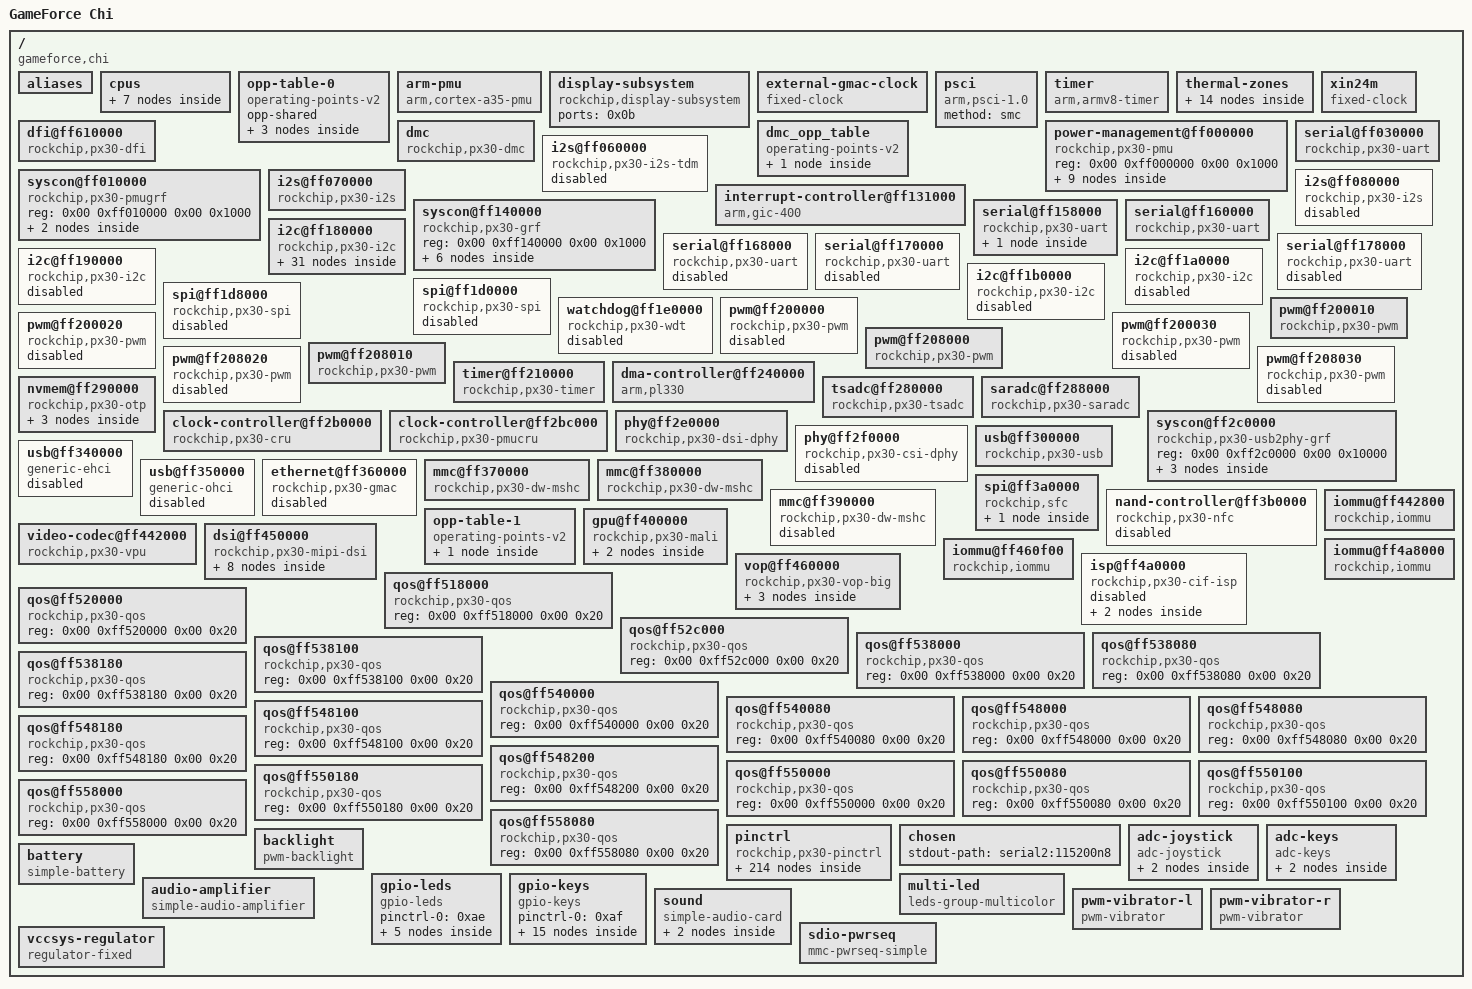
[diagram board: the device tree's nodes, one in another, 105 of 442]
/dts-v1/;

/ {
	compatible = "gameforce,chi\0rockchip,rk3326";
	interrupt-parent = <0x01>;
	#address-cells = <0x02>;
	#size-cells = <0x02>;
	model = "GameForce Chi";
	chassis-type = "handset";

	aliases {
		ethernet0 = "/ethernet@ff360000";
		i2c0 = "/i2c@ff180000";
		i2c1 = "/i2c@ff190000";
		i2c2 = "/i2c@ff1a0000";
		i2c3 = "/i2c@ff1b0000";
		serial0 = "/serial@ff030000";
		serial1 = "/serial@ff158000";
		serial2 = "/serial@ff160000";
		serial3 = "/serial@ff168000";
		serial4 = "/serial@ff170000";
		serial5 = "/serial@ff178000";
		spi0 = "/spi@ff1d0000";
		spi1 = "/spi@ff1d8000";
		mmc0 = "/mmc@ff370000";
		mmc1 = "/mmc@ff380000";
	};

	cpus {
		#address-cells = <0x02>;
		#size-cells = <0x00>;

		cpu@0 {
			device_type = "cpu";
			compatible = "arm,cortex-a35";
			reg = <0x00 0x00>;
			enable-method = "psci";
			clocks = <0x02 0x07>;
			#cooling-cells = <0x02>;
			cpu-idle-states = <0x03 0x04>;
			dynamic-power-coefficient = <0x5a>;
			operating-points-v2 = <0x05>;
			cpu-supply = <0x06>;
			phandle = <0x07>;
		};

		cpu@1 {
			device_type = "cpu";
			compatible = "arm,cortex-a35";
			reg = <0x00 0x01>;
			enable-method = "psci";
			clocks = <0x02 0x07>;
			#cooling-cells = <0x02>;
			cpu-idle-states = <0x03 0x04>;
			dynamic-power-coefficient = <0x5a>;
			operating-points-v2 = <0x05>;
			cpu-supply = <0x06>;
			phandle = <0x08>;
		};

		cpu@2 {
			device_type = "cpu";
			compatible = "arm,cortex-a35";
			reg = <0x00 0x02>;
			enable-method = "psci";
			clocks = <0x02 0x07>;
			#cooling-cells = <0x02>;
			cpu-idle-states = <0x03 0x04>;
			dynamic-power-coefficient = <0x5a>;
			operating-points-v2 = <0x05>;
			cpu-supply = <0x06>;
			phandle = <0x09>;
		};

		cpu@3 {
			device_type = "cpu";
			compatible = "arm,cortex-a35";
			reg = <0x00 0x03>;
			enable-method = "psci";
			clocks = <0x02 0x07>;
			#cooling-cells = <0x02>;
			cpu-idle-states = <0x03 0x04>;
			dynamic-power-coefficient = <0x5a>;
			operating-points-v2 = <0x05>;
			cpu-supply = <0x06>;
			phandle = <0x0a>;
		};

		idle-states {
			entry-method = "psci";

			cpu-sleep {
				compatible = "arm,idle-state";
				local-timer-stop;
				arm,psci-suspend-param = <0x10000>;
				entry-latency-us = <0x78>;
				exit-latency-us = <0xfa>;
				min-residency-us = <0x384>;
				phandle = <0x03>;
			};

			cluster-sleep {
				compatible = "arm,idle-state";
				local-timer-stop;
				arm,psci-suspend-param = <0x1010000>;
				entry-latency-us = <0x190>;
				exit-latency-us = <0x1f4>;
				min-residency-us = <0x7d0>;
				phandle = <0x04>;
			};
		};
	};

	opp-table-0 {
		compatible = "operating-points-v2";
		opp-shared;
		phandle = <0x05>;

		opp-1008000000 {
			opp-hz = <0x00 0x3c14dc00>;
			opp-microvolt = <0x11edd8 0x11edd8 0x149970>;
			clock-latency-ns = <0x9c40>;
		};

		opp-1296000000 {
			opp-hz = <0x00 0x4d3f6400>;
			opp-microvolt = <0x149970 0x149970 0x149970>;
			clock-latency-ns = <0x9c40>;
		};

		opp-1416000000 {
			opp-hz = <0x00 0x54667200>;
			opp-microvolt = <0x149970 0x149970 0x149970>;
			clock-latency-ns = <0x9c40>;
			turbo-mode;
		};
	};

	arm-pmu {
		compatible = "arm,cortex-a35-pmu";
		interrupts = <0x00 0x64 0x04 0x00 0x65 0x04 0x00 0x66 0x04 0x00 0x67 0x04>;
		interrupt-affinity = <0x07 0x08 0x09 0x0a>;
	};

	display-subsystem {
		compatible = "rockchip,display-subsystem";
		ports = <0x0b>;
		status = "okay";
	};

	external-gmac-clock {
		compatible = "fixed-clock";
		clock-frequency = <0x2faf080>;
		clock-output-names = "gmac_clkin";
		#clock-cells = <0x00>;
	};

	psci {
		compatible = "arm,psci-1.0";
		method = "smc";
	};

	timer {
		compatible = "arm,armv8-timer";
		interrupts = <0x01 0x0d 0xf04 0x01 0x0e 0xf04 0x01 0x0b 0xf04 0x01 0x0a 0xf04>;
	};

	thermal-zones {

		soc-thermal {
			polling-delay-passive = <0x14>;
			polling-delay = <0x3e8>;
			sustainable-power = <0x2ee>;
			thermal-sensors = <0x0c 0x00>;

			trips {

				trip-point-0 {
					temperature = <0x11170>;
					hysteresis = <0x7d0>;
					type = "passive";
				};

				trip-point-1 {
					temperature = <0x14c08>;
					hysteresis = <0x7d0>;
					type = "passive";
					phandle = <0x0d>;
				};

				soc-crit {
					temperature = <0x1c138>;
					hysteresis = <0x7d0>;
					type = "critical";
				};
			};

			cooling-maps {

				map0 {
					trip = <0x0d>;
					cooling-device = <0x07 0xffffffff 0xffffffff>;
					contribution = <0x1000>;
				};
			};
		};

		gpu-thermal {
			polling-delay-passive = <0x64>;
			polling-delay = <0x3e8>;
			thermal-sensors = <0x0c 0x01>;

			trips {

				gpu-threshold {
					temperature = <0x11170>;
					hysteresis = <0x7d0>;
					type = "passive";
				};

				gpu-target {
					temperature = <0x14c08>;
					hysteresis = <0x7d0>;
					type = "passive";
					phandle = <0x0e>;
				};

				gpu-crit {
					temperature = <0x1c138>;
					hysteresis = <0x7d0>;
					type = "critical";
				};
			};

			cooling-maps {

				map0 {
					trip = <0x0e>;
					cooling-device = <0x0f 0xffffffff 0xffffffff>;
				};
			};
		};
	};

	xin24m {
		compatible = "fixed-clock";
		#clock-cells = <0x00>;
		clock-frequency = <0x16e3600>;
		clock-output-names = "xin24m";
		phandle = <0x74>;
	};

	power-management@ff000000 {
		compatible = "rockchip,px30-pmu\0syscon\0simple-mfd";
		reg = <0x00 0xff000000 0x00 0x1000>;

		power-controller {
			compatible = "rockchip,px30-power-controller";
			#power-domain-cells = <0x01>;
			#address-cells = <0x01>;
			#size-cells = <0x00>;
			phandle = <0x76>;

			power-domain@5 {
				reg = <0x05>;
				clocks = <0x02 0x103 0x02 0x102 0x02 0x3c>;
				pm_qos = <0x10 0x11>;
				#power-domain-cells = <0x00>;
			};

			power-domain@7 {
				reg = <0x07>;
				clocks = <0x02 0xf7 0x02 0x3b>;
				pm_qos = <0x12>;
				#power-domain-cells = <0x00>;
			};

			power-domain@9 {
				reg = <0x09>;
				clocks = <0x02 0xb2 0x02 0x143 0x02 0x40 0x02 0x3f>;
				pm_qos = <0x13>;
				#power-domain-cells = <0x00>;
			};

			power-domain@10 {
				reg = <0x0a>;
				clocks = <0x02 0xfe 0x02 0x100 0x02 0xff 0x02 0x101 0x02 0x39 0x02 0x37 0x02 0x38 0x02 0x3a>;
				pm_qos = <0x14 0x15 0x16 0x17>;
				#power-domain-cells = <0x00>;
			};

			power-domain@11 {
				reg = <0x0b>;
				clocks = <0x02 0xaf 0x02 0xf4 0x02 0x4b>;
				pm_qos = <0x18 0x19>;
				#power-domain-cells = <0x00>;
			};

			power-domain@12 {
				reg = <0x0c>;
				clocks = <0x02 0xb7 0x02 0xb5 0x02 0xb6 0x02 0x96 0x02 0x97 0x02 0xfd 0x02 0xfb 0x02 0xfc 0x02 0x144 0x02 0x35 0x02 0x36>;
				pm_qos = <0x1a 0x1b 0x1c 0x1d>;
				#power-domain-cells = <0x00>;
			};

			power-domain@13 {
				reg = <0x0d>;
				clocks = <0x02 0xb3 0x02 0xb4 0x02 0xf9 0x02 0xfa 0x02 0x33>;
				pm_qos = <0x1e 0x1f 0x20 0x21 0x22>;
				#power-domain-cells = <0x00>;
			};

			power-domain@14 {
				reg = <0x0e>;
				clocks = <0x02 0x49>;
				pm_qos = <0x23>;
				#power-domain-cells = <0x00>;
			};
		};
	};

	dfi@ff610000 {
		reg = <0x00 0xff610000 0x00 0x400>;
		compatible = "rockchip,px30-dfi";
		rockchip,pmu = <0x24>;
		status = "okay";
		phandle = <0x25>;
	};

	dmc {
		compatible = "rockchip,px30-dmc";
		devfreq-events = <0x25>;
		clocks = <0x02 0x54>;
		clock-names = "dmc_clk";
		operating-points-v2 = <0x26>;
		uptreshold = <0x28>;
		downdifferential = <0x14>;
		status = "okay";
	};

	dmc_opp_table {
		compatible = "operating-points-v2";
		phandle = <0x26>;

		opp-924000000 {
			opp-hz = <0x00 0x37131f00>;
			opp-microvolt = <0x112a88>;
		};
	};

	syscon@ff010000 {
		compatible = "rockchip,px30-pmugrf\0syscon\0simple-mfd";
		reg = <0x00 0xff010000 0x00 0x1000>;
		#address-cells = <0x01>;
		#size-cells = <0x01>;
		phandle = <0x24>;

		io-domains {
			compatible = "rockchip,px30-pmu-io-voltage-domain";
			status = "okay";
			pmuio1-supply = <0x27>;
			pmuio2-supply = <0x28>;
		};

		reboot-mode {
			compatible = "syscon-reboot-mode";
			offset = <0x200>;
			mode-bootloader = <0x5242c301>;
			mode-fastboot = <0x5242c309>;
			mode-loader = <0x5242c301>;
			mode-normal = <0x5242c300>;
			mode-recovery = <0x5242c303>;
		};
	};

	serial@ff030000 {
		compatible = "rockchip,px30-uart\0snps,dw-apb-uart";
		reg = <0x00 0xff030000 0x00 0x100>;
		interrupts = <0x00 0x0f 0x04>;
		clocks = <0x29 0x06 0x29 0x15>;
		clock-names = "baudclk\0apb_pclk";
		dmas = <0x2a 0x00 0x2a 0x01>;
		dma-names = "tx\0rx";
		reg-shift = <0x02>;
		reg-io-width = <0x04>;
		pinctrl-names = "default";
		pinctrl-0 = <0x2b 0x2c 0x2d>;
		status = "okay";
	};

	i2s@ff060000 {
		compatible = "rockchip,px30-i2s-tdm";
		reg = <0x00 0xff060000 0x00 0x1000>;
		interrupts = <0x00 0x0c 0x04>;
		clocks = <0x02 0x10 0x02 0x12 0x02 0x106>;
		clock-names = "mclk_tx\0mclk_rx\0hclk";
		dmas = <0x2a 0x10 0x2a 0x11>;
		dma-names = "tx\0rx";
		rockchip,grf = <0x2e>;
		resets = <0x02 0x84 0x02 0xbf>;
		reset-names = "tx-m\0rx-m";
		pinctrl-names = "default";
		pinctrl-0 = <0x2f 0x30 0x31 0x32 0x33 0x34 0x35 0x36 0x37 0x38 0x39 0x3a>;
		#sound-dai-cells = <0x00>;
		status = "disabled";
	};

	i2s@ff070000 {
		compatible = "rockchip,px30-i2s\0rockchip,rk3066-i2s";
		reg = <0x00 0xff070000 0x00 0x1000>;
		interrupts = <0x00 0x0d 0x04>;
		clocks = <0x02 0x14 0x02 0x107>;
		clock-names = "i2s_clk\0i2s_hclk";
		dmas = <0x2a 0x12 0x2a 0x13>;
		dma-names = "tx\0rx";
		pinctrl-names = "default";
		pinctrl-0 = <0x3b 0x3c 0x3d 0x3e>;
		#sound-dai-cells = <0x00>;
		status = "okay";
		phandle = <0xb9>;
	};

	i2s@ff080000 {
		compatible = "rockchip,px30-i2s\0rockchip,rk3066-i2s";
		reg = <0x00 0xff080000 0x00 0x1000>;
		interrupts = <0x00 0x0e 0x04>;
		clocks = <0x02 0x16 0x02 0x108>;
		clock-names = "i2s_clk\0i2s_hclk";
		dmas = <0x2a 0x14 0x2a 0x15>;
		dma-names = "tx\0rx";
		pinctrl-names = "default";
		pinctrl-0 = <0x3f 0x40 0x41 0x42>;
		#sound-dai-cells = <0x00>;
		status = "disabled";
	};

	interrupt-controller@ff131000 {
		compatible = "arm,gic-400";
		#interrupt-cells = <0x03>;
		#address-cells = <0x00>;
		interrupt-controller;
		reg = <0x00 0xff131000 0x00 0x1000 0x00 0xff132000 0x00 0x2000 0x00 0xff134000 0x00 0x2000 0x00 0xff136000 0x00 0x2000>;
		interrupts = <0x01 0x09 0xf04>;
		phandle = <0x01>;
	};

	syscon@ff140000 {
		compatible = "rockchip,px30-grf\0syscon\0simple-mfd";
		reg = <0x00 0xff140000 0x00 0x1000>;
		#address-cells = <0x01>;
		#size-cells = <0x01>;
		phandle = <0x2e>;

		io-domains {
			compatible = "rockchip,px30-io-voltage-domain";
			status = "okay";
			vccio1-supply = <0x28>;
			vccio2-supply = <0x43>;
			vccio3-supply = <0x44>;
			vccio4-supply = <0x44>;
			vccio5-supply = <0x44>;
			vccio6-supply = <0x44>;
		};

		lvds {
			compatible = "rockchip,px30-lvds";
			phys = <0x45>;
			phy-names = "dphy";
			rockchip,grf = <0x2e>;
			rockchip,output = "lvds";
			status = "disabled";

			ports {
				#address-cells = <0x01>;
				#size-cells = <0x00>;

				port@0 {
					reg = <0x00>;
					#address-cells = <0x01>;
					#size-cells = <0x00>;

					endpoint@0 {
						reg = <0x00>;
						remote-endpoint = <0x46>;
						phandle = <0x9d>;
					};
				};

				port@1 {
					reg = <0x01>;
				};
			};
		};
	};

	serial@ff158000 {
		compatible = "rockchip,px30-uart\0snps,dw-apb-uart";
		reg = <0x00 0xff158000 0x00 0x100>;
		interrupts = <0x00 0x10 0x04>;
		clocks = <0x02 0x18 0x02 0x149>;
		clock-names = "baudclk\0apb_pclk";
		reg-shift = <0x02>;
		reg-io-width = <0x04>;
		pinctrl-names = "default";
		pinctrl-0 = <0x47 0x48 0x49>;
		status = "okay";
		uart-has-rtscts;

		bluetooth {
			compatible = "realtek,rtl8723ds-bt";
			device-wake-gpios = <0x4a 0x01 0x00>;
			enable-gpios = <0x4a 0x00 0x00>;
			host-wake-gpios = <0x4a 0x07 0x00>;
			pinctrl-0 = <0x4b 0x4c 0x4d>;
			pinctrl-names = "default";
		};
	};

	serial@ff160000 {
		compatible = "rockchip,px30-uart\0snps,dw-apb-uart";
		reg = <0x00 0xff160000 0x00 0x100>;
		interrupts = <0x00 0x11 0x04>;
		clocks = <0x02 0x19 0x02 0x14a>;
		clock-names = "baudclk\0apb_pclk";
		dmas = <0x2a 0x04 0x2a 0x05>;
		dma-names = "tx\0rx";
		reg-shift = <0x02>;
		reg-io-width = <0x04>;
		pinctrl-names = "default";
		pinctrl-0 = <0x4e>;
		status = "okay";
	};

	serial@ff168000 {
		compatible = "rockchip,px30-uart\0snps,dw-apb-uart";
		reg = <0x00 0xff168000 0x00 0x100>;
		interrupts = <0x00 0x12 0x04>;
		clocks = <0x02 0x1a 0x02 0x14b>;
		clock-names = "baudclk\0apb_pclk";
		dmas = <0x2a 0x06 0x2a 0x07>;
		dma-names = "tx\0rx";
		reg-shift = <0x02>;
		reg-io-width = <0x04>;
		pinctrl-names = "default";
		pinctrl-0 = <0x4f 0x50 0x51>;
		status = "disabled";
	};

	serial@ff170000 {
		compatible = "rockchip,px30-uart\0snps,dw-apb-uart";
		reg = <0x00 0xff170000 0x00 0x100>;
		interrupts = <0x00 0x13 0x04>;
		clocks = <0x02 0x1b 0x02 0x14c>;
		clock-names = "baudclk\0apb_pclk";
		dmas = <0x2a 0x08 0x2a 0x09>;
		dma-names = "tx\0rx";
		reg-shift = <0x02>;
		reg-io-width = <0x04>;
		pinctrl-names = "default";
		pinctrl-0 = <0x52 0x53 0x54>;
		status = "disabled";
	};

	serial@ff178000 {
		compatible = "rockchip,px30-uart\0snps,dw-apb-uart";
		reg = <0x00 0xff178000 0x00 0x100>;
		interrupts = <0x00 0x14 0x04>;
		clocks = <0x02 0x1c 0x02 0x14d>;
		clock-names = "baudclk\0apb_pclk";
		dmas = <0x2a 0x0a 0x2a 0x0b>;
		dma-names = "tx\0rx";
		reg-shift = <0x02>;
		reg-io-width = <0x04>;
		pinctrl-names = "default";
		pinctrl-0 = <0x55 0x56 0x57>;
		status = "disabled";
	};

	i2c@ff180000 {
		compatible = "rockchip,px30-i2c\0rockchip,rk3399-i2c";
		reg = <0x00 0xff180000 0x00 0x1000>;
		clocks = <0x02 0x1d 0x02 0x14e>;
		clock-names = "i2c\0pclk";
		interrupts = <0x00 0x07 0x04>;
		pinctrl-names = "default";
		pinctrl-0 = <0x58>;
		#address-cells = <0x01>;
		#size-cells = <0x00>;
		status = "okay";
		clock-frequency = <0x61a80>;
		i2c-scl-falling-time-ns = <0x10>;
		i2c-scl-rising-time-ns = <0x118>;

		pmic@20 {
			compatible = "rockchip,rk817";
			reg = <0x20>;
			#clock-cells = <0x01>;
			clock-names = "mclk";
			clock-output-names = "rk808-clkout1\0xin32k";
			clocks = <0x02 0x15>;
			interrupt-parent = <0x4a>;
			interrupts = <0x11 0x08>;
			pinctrl-0 = <0x59 0x5a>;
			pinctrl-names = "default";
			#sound-dai-cells = <0x00>;
			system-power-controller;
			wakeup-source;
			vcc1-supply = <0x5b>;
			vcc2-supply = <0x5b>;
			vcc3-supply = <0x5b>;
			vcc4-supply = <0x5b>;
			vcc5-supply = <0x5b>;
			vcc6-supply = <0x5b>;
			vcc7-supply = <0x44>;
			vcc8-supply = <0x5b>;
			vcc9-supply = <0x5c>;
			phandle = <0xb8>;

			regulators {

				DCDC_REG1 {
					regulator-always-on;
					regulator-boot-on;
					regulator-max-microvolt = <0x118c30>;
					regulator-min-microvolt = <0xe7ef0>;
					regulator-name = "vdd_logic";
					regulator-ramp-delay = <0x1771>;
					phandle = <0x93>;

					regulator-state-mem {
						regulator-on-in-suspend;
						regulator-suspend-microvolt = <0xe7ef0>;
					};
				};

				DCDC_REG2 {
					regulator-always-on;
					regulator-boot-on;
					regulator-max-microvolt = <0x149970>;
					regulator-min-microvolt = <0xe7ef0>;
					regulator-name = "vdd_arm";
					regulator-ramp-delay = <0x1771>;
					phandle = <0x06>;

					regulator-state-mem {
						regulator-off-in-suspend;
						regulator-suspend-microvolt = <0xe7ef0>;
					};
				};

				DCDC_REG3 {
					regulator-always-on;
					regulator-boot-on;
					regulator-name = "vcc_ddr";

					regulator-state-mem {
						regulator-on-in-suspend;
					};
				};

				DCDC_REG4 {
					regulator-always-on;
					regulator-boot-on;
					regulator-max-microvolt = <0x2dc6c0>;
					regulator-min-microvolt = <0x2dc6c0>;
					regulator-name = "vcc_3v0";
					phandle = <0x44>;

					regulator-state-mem {
						regulator-off-in-suspend;
						regulator-suspend-microvolt = <0x2dc6c0>;
					};
				};

				LDO_REG2 {
					regulator-always-on;
					regulator-boot-on;
					regulator-max-microvolt = <0x1b7740>;
					regulator-min-microvolt = <0x1b7740>;
					regulator-name = "vcc_1v8";
					phandle = <0x27>;

					regulator-state-mem {
						regulator-on-in-suspend;
						regulator-suspend-microvolt = <0x1b7740>;
					};
				};

				LDO_REG3 {
					regulator-always-on;
					regulator-boot-on;
					regulator-max-microvolt = <0xf4240>;
					regulator-min-microvolt = <0xf4240>;
					regulator-name = "vdd_1v0";

					regulator-state-mem {
						regulator-on-in-suspend;
						regulator-suspend-microvolt = <0xf4240>;
					};
				};

				LDO_REG4 {
					regulator-always-on;
					regulator-boot-on;
					regulator-max-microvolt = <0x2dc6c0>;
					regulator-min-microvolt = <0x2dc6c0>;
					regulator-name = "vcc_3v0_pmu";
					phandle = <0x28>;

					regulator-state-mem {
						regulator-on-in-suspend;
						regulator-suspend-microvolt = <0x2dc6c0>;
					};
				};

				LDO_REG5 {
					regulator-always-on;
					regulator-boot-on;
					regulator-max-microvolt = <0x325aa0>;
					regulator-min-microvolt = <0x1b7740>;
					regulator-name = "vccio_sd";
					phandle = <0x43>;

					regulator-state-mem {
						regulator-on-in-suspend;
						regulator-suspend-microvolt = <0x325aa0>;
					};
				};

				LDO_REG6 {
					regulator-boot-on;
					regulator-max-microvolt = <0x325aa0>;
					regulator-min-microvolt = <0x325aa0>;
					regulator-name = "vcc_sd";
					phandle = <0x7f>;

					regulator-state-mem {
						regulator-on-in-suspend;
						regulator-suspend-microvolt = <0x325aa0>;
					};
				};

				LDO_REG7 {
					regulator-max-microvolt = <0x325aa0>;
					regulator-min-microvolt = <0x325aa0>;
					regulator-name = "vcc_bl";
					phandle = <0xac>;

					regulator-state-mem {
						regulator-off-in-suspend;
						regulator-suspend-microvolt = <0x325aa0>;
					};
				};

				LDO_REG8 {
					regulator-max-microvolt = <0x2ab980>;
					regulator-min-microvolt = <0x2ab980>;
					regulator-name = "vcc_lcd";
					phandle = <0x98>;

					regulator-state-mem {
						regulator-off-in-suspend;
						regulator-suspend-microvolt = <0x2ab980>;
					};
				};

				LDO_REG9 {
					regulator-always-on;
					regulator-boot-on;
					regulator-max-microvolt = <0x325aa0>;
					regulator-min-microvolt = <0x325aa0>;
					regulator-name = "vcc_wifi";

					regulator-state-mem {
						regulator-off-in-suspend;
						regulator-suspend-microvolt = <0x325aa0>;
					};
				};

				BOOST {
					regulator-max-microvolt = <0x4c4b40>;
					regulator-min-microvolt = <0x4c4b40>;
					regulator-name = "dcdc_boost";
					phandle = <0x5c>;

					regulator-state-mem {
						regulator-off-in-suspend;
					};
				};

				OTG_SWITCH {
					regulator-name = "otg_switch";

					regulator-state-mem {
						regulator-off-in-suspend;
					};
				};
			};

			charger {
				monitored-battery = <0x5d>;
				rockchip,resistor-sense-micro-ohms = <0x2710>;
				rockchip,sleep-enter-current-microamp = <0x493e0>;
				rockchip,sleep-filter-current-microamp = <0x186a0>;
			};
		};
	};

	i2c@ff190000 {
		compatible = "rockchip,px30-i2c\0rockchip,rk3399-i2c";
		reg = <0x00 0xff190000 0x00 0x1000>;
		clocks = <0x02 0x1e 0x02 0x14f>;
		clock-names = "i2c\0pclk";
		interrupts = <0x00 0x08 0x04>;
		pinctrl-names = "default";
		pinctrl-0 = <0x5e>;
		#address-cells = <0x01>;
		#size-cells = <0x00>;
		status = "disabled";
	};

	i2c@ff1a0000 {
		compatible = "rockchip,px30-i2c\0rockchip,rk3399-i2c";
		reg = <0x00 0xff1a0000 0x00 0x1000>;
		clocks = <0x02 0x1f 0x02 0x150>;
		clock-names = "i2c\0pclk";
		interrupts = <0x00 0x09 0x04>;
		pinctrl-names = "default";
		pinctrl-0 = <0x5f>;
		#address-cells = <0x01>;
		#size-cells = <0x00>;
		status = "disabled";
	};

	i2c@ff1b0000 {
		compatible = "rockchip,px30-i2c\0rockchip,rk3399-i2c";
		reg = <0x00 0xff1b0000 0x00 0x1000>;
		clocks = <0x02 0x20 0x02 0x151>;
		clock-names = "i2c\0pclk";
		interrupts = <0x00 0x0a 0x04>;
		pinctrl-names = "default";
		pinctrl-0 = <0x60>;
		#address-cells = <0x01>;
		#size-cells = <0x00>;
		status = "disabled";
	};

	spi@ff1d0000 {
		compatible = "rockchip,px30-spi\0rockchip,rk3066-spi";
		reg = <0x00 0xff1d0000 0x00 0x1000>;
		interrupts = <0x00 0x1a 0x04>;
		clocks = <0x02 0x24 0x02 0x155>;
		clock-names = "spiclk\0apb_pclk";
		dmas = <0x2a 0x0c 0x2a 0x0d>;
		dma-names = "tx\0rx";
		num-cs = <0x02>;
		pinctrl-names = "default";
		pinctrl-0 = <0x61 0x62 0x63 0x64>;
		#address-cells = <0x01>;
		#size-cells = <0x00>;
		status = "disabled";
	};

	spi@ff1d8000 {
		compatible = "rockchip,px30-spi\0rockchip,rk3066-spi";
		reg = <0x00 0xff1d8000 0x00 0x1000>;
		interrupts = <0x00 0x1b 0x04>;
		clocks = <0x02 0x25 0x02 0x156>;
		clock-names = "spiclk\0apb_pclk";
		dmas = <0x2a 0x0e 0x2a 0x0f>;
		dma-names = "tx\0rx";
		num-cs = <0x02>;
		pinctrl-names = "default";
		pinctrl-0 = <0x65 0x66 0x67 0x68 0x69>;
		#address-cells = <0x01>;
		#size-cells = <0x00>;
		status = "disabled";
	};

	watchdog@ff1e0000 {
		compatible = "rockchip,px30-wdt\0snps,dw-wdt";
		reg = <0x00 0xff1e0000 0x00 0x100>;
		clocks = <0x02 0x15b>;
		interrupts = <0x00 0x25 0x04>;
		status = "disabled";
	};

	pwm@ff200000 {
		compatible = "rockchip,px30-pwm\0rockchip,rk3328-pwm";
		reg = <0x00 0xff200000 0x00 0x10>;
		clocks = <0x02 0x22 0x02 0x153>;
		clock-names = "pwm\0pclk";
		pinctrl-names = "default";
		pinctrl-0 = <0x6a>;
		#pwm-cells = <0x03>;
		status = "disabled";
	};

	pwm@ff200010 {
		compatible = "rockchip,px30-pwm\0rockchip,rk3328-pwm";
		reg = <0x00 0xff200010 0x00 0x10>;
		clocks = <0x02 0x22 0x02 0x153>;
		clock-names = "pwm\0pclk";
		pinctrl-names = "default";
		pinctrl-0 = <0x6b>;
		#pwm-cells = <0x03>;
		status = "okay";
		phandle = <0xad>;
	};

	pwm@ff200020 {
		compatible = "rockchip,px30-pwm\0rockchip,rk3328-pwm";
		reg = <0x00 0xff200020 0x00 0x10>;
		clocks = <0x02 0x22 0x02 0x153>;
		clock-names = "pwm\0pclk";
		pinctrl-names = "default";
		pinctrl-0 = <0x6c>;
		#pwm-cells = <0x03>;
		status = "disabled";
	};

	pwm@ff200030 {
		compatible = "rockchip,px30-pwm\0rockchip,rk3328-pwm";
		reg = <0x00 0xff200030 0x00 0x10>;
		clocks = <0x02 0x22 0x02 0x153>;
		clock-names = "pwm\0pclk";
		pinctrl-names = "default";
		pinctrl-0 = <0x6d>;
		#pwm-cells = <0x03>;
		status = "disabled";
	};

	pwm@ff208000 {
		compatible = "rockchip,px30-pwm\0rockchip,rk3328-pwm";
		reg = <0x00 0xff208000 0x00 0x10>;
		clocks = <0x02 0x23 0x02 0x154>;
		clock-names = "pwm\0pclk";
		pinctrl-names = "default";
		pinctrl-0 = <0x6e>;
		#pwm-cells = <0x03>;
		status = "okay";
		phandle = <0xba>;
	};

	pwm@ff208010 {
		compatible = "rockchip,px30-pwm\0rockchip,rk3328-pwm";
		reg = <0x00 0xff208010 0x00 0x10>;
		clocks = <0x02 0x23 0x02 0x154>;
		clock-names = "pwm\0pclk";
		pinctrl-names = "default";
		pinctrl-0 = <0x6f>;
		#pwm-cells = <0x03>;
		status = "okay";
		phandle = <0xbb>;
	};

	pwm@ff208020 {
		compatible = "rockchip,px30-pwm\0rockchip,rk3328-pwm";
		reg = <0x00 0xff208020 0x00 0x10>;
		clocks = <0x02 0x23 0x02 0x154>;
		clock-names = "pwm\0pclk";
		pinctrl-names = "default";
		pinctrl-0 = <0x70>;
		#pwm-cells = <0x03>;
		status = "disabled";
	};

	pwm@ff208030 {
		compatible = "rockchip,px30-pwm\0rockchip,rk3328-pwm";
		reg = <0x00 0xff208030 0x00 0x10>;
		clocks = <0x02 0x23 0x02 0x154>;
		clock-names = "pwm\0pclk";
		pinctrl-names = "default";
		pinctrl-0 = <0x71>;
		#pwm-cells = <0x03>;
		status = "disabled";
	};

	timer@ff210000 {
		compatible = "rockchip,px30-timer\0rockchip,rk3288-timer";
		reg = <0x00 0xff210000 0x00 0x1000>;
		interrupts = <0x00 0x1e 0x04>;
		clocks = <0x02 0x159 0x02 0x26>;
		clock-names = "pclk\0timer";
	};

	dma-controller@ff240000 {
		compatible = "arm,pl330\0arm,primecell";
		reg = <0x00 0xff240000 0x00 0x4000>;
		interrupts = <0x00 0x01 0x04 0x00 0x02 0x04>;
		arm,pl330-periph-burst;
		clocks = <0x02 0xbb>;
		clock-names = "apb_pclk";
		#dma-cells = <0x01>;
		phandle = <0x2a>;
	};

	tsadc@ff280000 {
		compatible = "rockchip,px30-tsadc";
		reg = <0x00 0xff280000 0x00 0x100>;
		interrupts = <0x00 0x24 0x04>;
		assigned-clocks = <0x02 0x2c>;
		assigned-clock-rates = <0xc350>;
		clocks = <0x02 0x2c 0x02 0x158>;
		clock-names = "tsadc\0apb_pclk";
		resets = <0x02 0xa8>;
		reset-names = "tsadc-apb";
		rockchip,grf = <0x2e>;
		rockchip,hw-tshut-temp = <0x1d4c0>;
		pinctrl-names = "init\0default\0sleep";
		pinctrl-0 = <0x72>;
		pinctrl-1 = <0x73>;
		pinctrl-2 = <0x72>;
		#thermal-sensor-cells = <0x01>;
		status = "okay";
		phandle = <0x0c>;
	};

	saradc@ff288000 {
		compatible = "rockchip,px30-saradc\0rockchip,rk3399-saradc";
		reg = <0x00 0xff288000 0x00 0x100>;
		interrupts = <0x00 0x54 0x04>;
		#io-channel-cells = <0x01>;
		clocks = <0x02 0x2d 0x02 0x157>;
		clock-names = "saradc\0apb_pclk";
		resets = <0x02 0xa5>;
		reset-names = "saradc-apb";
		status = "okay";
		vref-supply = <0x27>;
		phandle = <0xab>;
	};

	nvmem@ff290000 {
		compatible = "rockchip,px30-otp";
		reg = <0x00 0xff290000 0x00 0x4000>;
		clocks = <0x02 0x2f 0x02 0x15a 0x02 0x161>;
		clock-names = "otp\0apb_pclk\0phy";
		resets = <0x02 0xb4>;
		reset-names = "phy";
		#address-cells = <0x01>;
		#size-cells = <0x01>;

		id@7 {
			reg = <0x07 0x10>;
		};

		cpu-leakage@17 {
			reg = <0x17 0x01>;
		};

		performance@1e {
			reg = <0x1e 0x01>;
			bits = <0x04 0x03>;
		};
	};

	clock-controller@ff2b0000 {
		compatible = "rockchip,px30-cru";
		reg = <0x00 0xff2b0000 0x00 0x1000>;
		clocks = <0x74 0x29 0x01>;
		clock-names = "xin24m\0gpll";
		rockchip,grf = <0x2e>;
		#clock-cells = <0x01>;
		#reset-cells = <0x01>;
		assigned-clocks = <0x02 0x04 0x02 0xab 0x02 0xb0 0x02 0xf0 0x02 0xf5 0x02 0x140 0x02 0x49>;
		assigned-clock-rates = <0x46cf7100 0xbebc200 0xbebc200 0x8f0d180 0x8f0d180 0x5f5e100 0xbebc200>;
		phandle = <0x02>;
	};

	clock-controller@ff2bc000 {
		compatible = "rockchip,px30-pmucru";
		reg = <0x00 0xff2bc000 0x00 0x1000>;
		clocks = <0x74>;
		clock-names = "xin24m";
		rockchip,grf = <0x2e>;
		#clock-cells = <0x01>;
		#reset-cells = <0x01>;
		assigned-clocks = <0x29 0x01 0x29 0x08 0x29 0x05>;
		assigned-clock-rates = <0x47868c00 0x5f5e100 0x18cba80>;
		phandle = <0x29>;
	};

	syscon@ff2c0000 {
		compatible = "rockchip,px30-usb2phy-grf\0syscon\0simple-mfd";
		reg = <0x00 0xff2c0000 0x00 0x10000>;
		#address-cells = <0x01>;
		#size-cells = <0x01>;

		usb2phy@100 {
			compatible = "rockchip,px30-usb2phy";
			reg = <0x100 0x20>;
			clocks = <0x29 0x0a>;
			clock-names = "phyclk";
			#clock-cells = <0x00>;
			assigned-clocks = <0x02 0x0e>;
			assigned-clock-parents = <0x75>;
			clock-output-names = "usb480m_phy";
			status = "okay";
			phandle = <0x75>;

			host-port {
				#phy-cells = <0x00>;
				interrupts = <0x00 0x44 0x04>;
				interrupt-names = "linestate";
				status = "disabled";
				phandle = <0x78>;
			};

			otg-port {
				#phy-cells = <0x00>;
				interrupts = <0x00 0x42 0x04 0x00 0x41 0x04 0x00 0x40 0x04>;
				interrupt-names = "otg-bvalid\0otg-id\0linestate";
				status = "okay";
				phandle = <0x77>;
			};
		};
	};

	phy@ff2e0000 {
		compatible = "rockchip,px30-dsi-dphy";
		reg = <0x00 0xff2e0000 0x00 0x10000>;
		clocks = <0x29 0x0b 0x02 0x145>;
		clock-names = "ref\0pclk";
		resets = <0x02 0x3e>;
		reset-names = "apb";
		#phy-cells = <0x00>;
		power-domains = <0x76 0x0c>;
		status = "okay";
		phandle = <0x45>;
	};

	phy@ff2f0000 {
		compatible = "rockchip,px30-csi-dphy";
		reg = <0x00 0xff2f0000 0x00 0x4000>;
		clocks = <0x02 0x146>;
		clock-names = "pclk";
		#phy-cells = <0x00>;
		power-domains = <0x76 0x0d>;
		resets = <0x02 0x2f>;
		reset-names = "apb";
		rockchip,grf = <0x2e>;
		status = "disabled";
		phandle = <0x9f>;
	};

	usb@ff300000 {
		compatible = "rockchip,px30-usb\0rockchip,rk3066-usb\0snps,dwc2";
		reg = <0x00 0xff300000 0x00 0x40000>;
		interrupts = <0x00 0x3e 0x04>;
		clocks = <0x02 0x102>;
		clock-names = "otg";
		dr_mode = "otg";
		usb-role-switch;
		role-switch-default-mode = "host";
		g-np-tx-fifo-size = <0x10>;
		g-rx-fifo-size = <0x118>;
		g-tx-fifo-size = <0x100 0x80 0x80 0x40 0x20 0x10>;
		phys = <0x77>;
		phy-names = "usb2-phy";
		power-domains = <0x76 0x05>;
		status = "okay";
	};

	usb@ff340000 {
		compatible = "generic-ehci";
		reg = <0x00 0xff340000 0x00 0x10000>;
		interrupts = <0x00 0x3c 0x04>;
		clocks = <0x02 0x103>;
		phys = <0x78>;
		phy-names = "usb";
		power-domains = <0x76 0x05>;
		status = "disabled";
	};

	usb@ff350000 {
		compatible = "generic-ohci";
		reg = <0x00 0xff350000 0x00 0x10000>;
		interrupts = <0x00 0x3d 0x04>;
		clocks = <0x02 0x103>;
		phys = <0x78>;
		phy-names = "usb";
		power-domains = <0x76 0x05>;
		status = "disabled";
	};

	ethernet@ff360000 {
		compatible = "rockchip,px30-gmac";
		reg = <0x00 0xff360000 0x00 0x10000>;
		interrupts = <0x00 0x2b 0x04>;
		interrupt-names = "macirq";
		clocks = <0x02 0x3e 0x02 0x3f 0x02 0x3f 0x02 0x40 0x02 0x41 0x02 0xb2 0x02 0x143 0x02 0x4c>;
		clock-names = "stmmaceth\0mac_clk_rx\0mac_clk_tx\0clk_mac_ref\0clk_mac_refout\0aclk_mac\0pclk_mac\0clk_mac_speed";
		rockchip,grf = <0x2e>;
		phy-mode = "rmii";
		pinctrl-names = "default";
		pinctrl-0 = <0x79 0x7a>;
		power-domains = <0x76 0x09>;
		resets = <0x02 0x5e>;
		reset-names = "stmmaceth";
		status = "disabled";
	};

	mmc@ff370000 {
		compatible = "rockchip,px30-dw-mshc\0rockchip,rk3288-dw-mshc";
		reg = <0x00 0xff370000 0x00 0x4000>;
		interrupts = <0x00 0x36 0x04>;
		clocks = <0x02 0xf7 0x02 0x3b 0x02 0x43 0x02 0x44>;
		clock-names = "biu\0ciu\0ciu-drive\0ciu-sample";
		bus-width = <0x04>;
		fifo-depth = <0x100>;
		max-frequency = <0x8f0d180>;
		pinctrl-names = "default";
		pinctrl-0 = <0x7b 0x7c 0x7d 0x7e>;
		power-domains = <0x76 0x07>;
		status = "okay";
		cap-mmc-highspeed;
		cap-sd-highspeed;
		no-sdio;
		sd-uhs-sdr12;
		sd-uhs-sdr25;
		sd-uhs-sdr50;
		sd-uhs-sdr104;
		vmmc-supply = <0x7f>;
		vqmmc-supply = <0x43>;
	};

	mmc@ff380000 {
		compatible = "rockchip,px30-dw-mshc\0rockchip,rk3288-dw-mshc";
		reg = <0x00 0xff380000 0x00 0x4000>;
		interrupts = <0x00 0x37 0x04>;
		clocks = <0x02 0xff 0x02 0x38 0x02 0x45 0x02 0x46>;
		clock-names = "biu\0ciu\0ciu-drive\0ciu-sample";
		bus-width = <0x04>;
		fifo-depth = <0x100>;
		max-frequency = <0x8f0d180>;
		pinctrl-names = "default";
		pinctrl-0 = <0x80 0x81 0x82>;
		power-domains = <0x76 0x0a>;
		status = "okay";
		cap-sd-highspeed;
		cap-sdio-irq;
		disable-wp;
		keep-power-in-suspend;
		mmc-pwrseq = <0x83>;
		no-mmc;
		no-sd;
		non-removable;
		sd-uhs-sdr104;
	};

	mmc@ff390000 {
		compatible = "rockchip,px30-dw-mshc\0rockchip,rk3288-dw-mshc";
		reg = <0x00 0xff390000 0x00 0x4000>;
		interrupts = <0x00 0x35 0x04>;
		clocks = <0x02 0x100 0x02 0x39 0x02 0x47 0x02 0x48>;
		clock-names = "biu\0ciu\0ciu-drive\0ciu-sample";
		bus-width = <0x08>;
		fifo-depth = <0x100>;
		max-frequency = <0x8f0d180>;
		pinctrl-names = "default";
		pinctrl-0 = <0x84 0x85 0x86>;
		power-domains = <0x76 0x0a>;
		status = "disabled";
	};

	spi@ff3a0000 {
		compatible = "rockchip,sfc";
		reg = <0x00 0xff3a0000 0x00 0x4000>;
		interrupts = <0x00 0x38 0x04>;
		clocks = <0x02 0x3a 0x02 0x101>;
		clock-names = "clk_sfc\0hclk_sfc";
		pinctrl-0 = <0x87 0x88 0x89>;
		pinctrl-names = "default";
		power-domains = <0x76 0x0a>;
		status = "okay";
		#address-cells = <0x01>;
		#size-cells = <0x00>;

		flash@0 {
			compatible = "jedec,spi-nor";
			reg = <0x00>;
			spi-max-frequency = <0x66ff300>;
			spi-rx-bus-width = <0x02>;
			spi-tx-bus-width = <0x01>;
		};
	};

	nand-controller@ff3b0000 {
		compatible = "rockchip,px30-nfc";
		reg = <0x00 0xff3b0000 0x00 0x4000>;
		interrupts = <0x00 0x39 0x04>;
		clocks = <0x02 0xfe 0x02 0x37>;
		clock-names = "ahb\0nfc";
		assigned-clocks = <0x02 0x37>;
		assigned-clock-rates = <0x8f0d180>;
		pinctrl-names = "default";
		pinctrl-0 = <0x8a 0x8b 0x8c 0x8d 0x8e 0x8f 0x90 0x91>;
		power-domains = <0x76 0x0a>;
		status = "disabled";
	};

	opp-table-1 {
		compatible = "operating-points-v2";
		phandle = <0x92>;

		opp-560000000 {
			opp-hz = <0x00 0x2160ec00>;
			opp-microvolt = <0x118c30>;
		};
	};

	gpu@ff400000 {
		compatible = "rockchip,px30-mali\0arm,mali-bifrost";
		reg = <0x00 0xff400000 0x00 0x4000>;
		interrupts = <0x00 0x2f 0x04 0x00 0x2e 0x04 0x00 0x2d 0x04>;
		interrupt-names = "job\0mmu\0gpu";
		clocks = <0x02 0x49>;
		clock-names = "bus";
		resets = <0x02 0x12>;
		#cooling-cells = <0x02>;
		power-domains = <0x76 0x0e>;
		power_policy = "coarse_demand";
		operating-points-v2 = <0x92>;
		status = "okay";
		mali-supply = <0x93>;
		phandle = <0x0f>;

		power_model@0 {
			compatible = "arm,mali-simple-power-model";
			static-coefficient = <0x186a0>;
			dynamic-coefficient = <0x3b9>;
			ts = <0xfffe56a6 0xf87a 0xfffffab5 0x14>;
			thermal-zone = "gpu-thermal";
		};

		power_model@1 {
			compatible = "arm,mali-g31-power-model";
			scale = <0x05>;
		};
	};

	video-codec@ff442000 {
		compatible = "rockchip,px30-vpu";
		reg = <0x00 0xff442000 0x00 0x800>;
		interrupts = <0x00 0x50 0x04 0x00 0x4f 0x04>;
		interrupt-names = "vepu\0vdpu";
		clocks = <0x02 0xaf 0x02 0xf4>;
		clock-names = "aclk\0hclk";
		iommus = <0x94>;
		power-domains = <0x76 0x0b>;
	};

	iommu@ff442800 {
		compatible = "rockchip,iommu";
		reg = <0x00 0xff442800 0x00 0x100>;
		interrupts = <0x00 0x51 0x04>;
		clocks = <0x02 0xaf 0x02 0xf4>;
		clock-names = "aclk\0iface";
		#iommu-cells = <0x00>;
		power-domains = <0x76 0x0b>;
		phandle = <0x94>;
	};

	dsi@ff450000 {
		compatible = "rockchip,px30-mipi-dsi\0snps,dw-mipi-dsi";
		reg = <0x00 0xff450000 0x00 0x10000>;
		interrupts = <0x00 0x4b 0x04>;
		clocks = <0x02 0x144>;
		clock-names = "pclk";
		phys = <0x45>;
		phy-names = "dphy";
		power-domains = <0x76 0x0c>;
		resets = <0x02 0x3d>;
		reset-names = "apb";
		rockchip,grf = <0x2e>;
		#address-cells = <0x01>;
		#size-cells = <0x00>;
		status = "okay";

		ports {
			#address-cells = <0x01>;
			#size-cells = <0x00>;

			port@0 {
				reg = <0x00>;
				#address-cells = <0x01>;
				#size-cells = <0x00>;

				endpoint@0 {
					reg = <0x00>;
					remote-endpoint = <0x95>;
					phandle = <0x9c>;
				};
			};

			port@1 {
				reg = <0x01>;

				endpoint {
					remote-endpoint = <0x96>;
					phandle = <0x9a>;
				};
			};
		};

		panel@0 {
			reg = <0x00>;
			compatible = "gameforce,chi-panel";
			backlight = <0x97>;
			iovcc-supply = <0x98>;
			vcc-supply = <0x98>;
			reset-gpios = <0x99 0x00 0x01>;

			port {

				endpoint {
					remote-endpoint = <0x9a>;
					phandle = <0x96>;
				};
			};
		};
	};

	vop@ff460000 {
		compatible = "rockchip,px30-vop-big";
		reg = <0x00 0xff460000 0x00 0xefc>;
		interrupts = <0x00 0x4d 0x04>;
		clocks = <0x02 0xb5 0x02 0x96 0x02 0xfb>;
		clock-names = "aclk_vop\0dclk_vop\0hclk_vop";
		resets = <0x02 0x33 0x02 0x34 0x02 0x35>;
		reset-names = "axi\0ahb\0dclk";
		iommus = <0x9b>;
		power-domains = <0x76 0x0c>;
		status = "okay";

		port {
			#address-cells = <0x01>;
			#size-cells = <0x00>;
			phandle = <0x0b>;

			endpoint@0 {
				reg = <0x00>;
				remote-endpoint = <0x9c>;
				phandle = <0x95>;
			};

			endpoint@1 {
				reg = <0x01>;
				remote-endpoint = <0x9d>;
				phandle = <0x46>;
			};
		};
	};

	iommu@ff460f00 {
		compatible = "rockchip,iommu";
		reg = <0x00 0xff460f00 0x00 0x100>;
		interrupts = <0x00 0x4d 0x04>;
		clocks = <0x02 0xb5 0x02 0xfb>;
		clock-names = "aclk\0iface";
		power-domains = <0x76 0x0c>;
		#iommu-cells = <0x00>;
		status = "okay";
		phandle = <0x9b>;
	};

	isp@ff4a0000 {
		compatible = "rockchip,px30-cif-isp";
		reg = <0x00 0xff4a0000 0x00 0x8000>;
		interrupts = <0x00 0x46 0x04 0x00 0x49 0x04 0x00 0x4a 0x04>;
		interrupt-names = "isp\0mi\0mipi";
		clocks = <0x02 0x33 0x02 0xb4 0x02 0xfa 0x02 0x15f>;
		clock-names = "isp\0aclk\0hclk\0pclk";
		iommus = <0x9e>;
		phys = <0x9f>;
		phy-names = "dphy";
		power-domains = <0x76 0x0d>;
		status = "disabled";

		ports {
			#address-cells = <0x01>;
			#size-cells = <0x00>;

			port@0 {
				reg = <0x00>;
				#address-cells = <0x01>;
				#size-cells = <0x00>;
			};
		};
	};

	iommu@ff4a8000 {
		compatible = "rockchip,iommu";
		reg = <0x00 0xff4a8000 0x00 0x100>;
		interrupts = <0x00 0x46 0x04>;
		clocks = <0x02 0xb4 0x02 0xfa>;
		clock-names = "aclk\0iface";
		power-domains = <0x76 0x0d>;
		rockchip,disable-mmu-reset;
		#iommu-cells = <0x00>;
		phandle = <0x9e>;
	};

	qos@ff518000 {
		compatible = "rockchip,px30-qos\0syscon";
		reg = <0x00 0xff518000 0x00 0x20>;
		phandle = <0x13>;
	};

	qos@ff520000 {
		compatible = "rockchip,px30-qos\0syscon";
		reg = <0x00 0xff520000 0x00 0x20>;
		phandle = <0x23>;
	};

	qos@ff52c000 {
		compatible = "rockchip,px30-qos\0syscon";
		reg = <0x00 0xff52c000 0x00 0x20>;
		phandle = <0x12>;
	};

	qos@ff538000 {
		compatible = "rockchip,px30-qos\0syscon";
		reg = <0x00 0xff538000 0x00 0x20>;
		phandle = <0x14>;
	};

	qos@ff538080 {
		compatible = "rockchip,px30-qos\0syscon";
		reg = <0x00 0xff538080 0x00 0x20>;
		phandle = <0x15>;
	};

	qos@ff538100 {
		compatible = "rockchip,px30-qos\0syscon";
		reg = <0x00 0xff538100 0x00 0x20>;
		phandle = <0x16>;
	};

	qos@ff538180 {
		compatible = "rockchip,px30-qos\0syscon";
		reg = <0x00 0xff538180 0x00 0x20>;
		phandle = <0x17>;
	};

	qos@ff540000 {
		compatible = "rockchip,px30-qos\0syscon";
		reg = <0x00 0xff540000 0x00 0x20>;
		phandle = <0x10>;
	};

	qos@ff540080 {
		compatible = "rockchip,px30-qos\0syscon";
		reg = <0x00 0xff540080 0x00 0x20>;
		phandle = <0x11>;
	};

	qos@ff548000 {
		compatible = "rockchip,px30-qos\0syscon";
		reg = <0x00 0xff548000 0x00 0x20>;
		phandle = <0x1e>;
	};

	qos@ff548080 {
		compatible = "rockchip,px30-qos\0syscon";
		reg = <0x00 0xff548080 0x00 0x20>;
		phandle = <0x1f>;
	};

	qos@ff548100 {
		compatible = "rockchip,px30-qos\0syscon";
		reg = <0x00 0xff548100 0x00 0x20>;
		phandle = <0x20>;
	};

	qos@ff548180 {
		compatible = "rockchip,px30-qos\0syscon";
		reg = <0x00 0xff548180 0x00 0x20>;
		phandle = <0x21>;
	};

	qos@ff548200 {
		compatible = "rockchip,px30-qos\0syscon";
		reg = <0x00 0xff548200 0x00 0x20>;
		phandle = <0x22>;
	};

	qos@ff550000 {
		compatible = "rockchip,px30-qos\0syscon";
		reg = <0x00 0xff550000 0x00 0x20>;
		phandle = <0x1a>;
	};

	qos@ff550080 {
		compatible = "rockchip,px30-qos\0syscon";
		reg = <0x00 0xff550080 0x00 0x20>;
		phandle = <0x1b>;
	};

	qos@ff550100 {
		compatible = "rockchip,px30-qos\0syscon";
		reg = <0x00 0xff550100 0x00 0x20>;
		phandle = <0x1c>;
	};

	qos@ff550180 {
		compatible = "rockchip,px30-qos\0syscon";
		reg = <0x00 0xff550180 0x00 0x20>;
		phandle = <0x1d>;
	};

	qos@ff558000 {
		compatible = "rockchip,px30-qos\0syscon";
		reg = <0x00 0xff558000 0x00 0x20>;
		phandle = <0x18>;
	};

	qos@ff558080 {
		compatible = "rockchip,px30-qos\0syscon";
		reg = <0x00 0xff558080 0x00 0x20>;
		phandle = <0x19>;
	};

	pinctrl {
		compatible = "rockchip,px30-pinctrl";
		rockchip,grf = <0x2e>;
		rockchip,pmu = <0x24>;
		#address-cells = <0x02>;
		#size-cells = <0x02>;
		ranges;

		gpio@ff040000 {
			compatible = "rockchip,gpio-bank";
			reg = <0x00 0xff040000 0x00 0x100>;
			interrupts = <0x00 0x03 0x04>;
			clocks = <0x29 0x14>;
			gpio-controller;
			#gpio-cells = <0x02>;
			interrupt-controller;
			#interrupt-cells = <0x02>;
			phandle = <0x4a>;
		};

		gpio@ff250000 {
			compatible = "rockchip,gpio-bank";
			reg = <0x00 0xff250000 0x00 0x100>;
			interrupts = <0x00 0x04 0x04>;
			clocks = <0x02 0x15c>;
			gpio-controller;
			#gpio-cells = <0x02>;
			interrupt-controller;
			#interrupt-cells = <0x02>;
			phandle = <0xb1>;
		};

		gpio@ff260000 {
			compatible = "rockchip,gpio-bank";
			reg = <0x00 0xff260000 0x00 0x100>;
			interrupts = <0x00 0x05 0x04>;
			clocks = <0x02 0x15d>;
			gpio-controller;
			#gpio-cells = <0x02>;
			interrupt-controller;
			#interrupt-cells = <0x02>;
			phandle = <0xb0>;
		};

		gpio@ff270000 {
			compatible = "rockchip,gpio-bank";
			reg = <0x00 0xff270000 0x00 0x100>;
			interrupts = <0x00 0x06 0x04>;
			clocks = <0x02 0x15e>;
			gpio-controller;
			#gpio-cells = <0x02>;
			interrupt-controller;
			#interrupt-cells = <0x02>;
			phandle = <0x99>;
		};

		pcfg-pull-up {
			bias-pull-up;
			phandle = <0xa2>;
		};

		pcfg-pull-down {
			bias-pull-down;
			phandle = <0xa9>;
		};

		pcfg-pull-none {
			bias-disable;
			phandle = <0xa1>;
		};

		pcfg-pull-none-2ma {
			bias-disable;
			drive-strength = <0x02>;
		};

		pcfg-pull-up-2ma {
			bias-pull-up;
			drive-strength = <0x02>;
		};

		pcfg-pull-up-4ma {
			bias-pull-up;
			drive-strength = <0x04>;
			phandle = <0xa3>;
		};

		pcfg-pull-none-4ma {
			bias-disable;
			drive-strength = <0x04>;
		};

		pcfg-pull-down-4ma {
			bias-pull-down;
			drive-strength = <0x04>;
		};

		pcfg-pull-none-8ma {
			bias-disable;
			drive-strength = <0x08>;
			phandle = <0xa6>;
		};

		pcfg-pull-up-8ma {
			bias-pull-up;
			drive-strength = <0x08>;
			phandle = <0xa4>;
		};

		pcfg-pull-none-12ma {
			bias-disable;
			drive-strength = <0x0c>;
			phandle = <0xa8>;
		};

		pcfg-pull-up-12ma {
			bias-pull-up;
			drive-strength = <0x0c>;
			phandle = <0xa7>;
		};

		pcfg-pull-none-smt {
			bias-disable;
			input-schmitt-enable;
			phandle = <0xa0>;
		};

		pcfg-output-high {
			output-high;
		};

		pcfg-output-low {
			output-low;
			phandle = <0xaa>;
		};

		pcfg-input-high {
			bias-pull-up;
			input-enable;
			phandle = <0xa5>;
		};

		pcfg-input {
			input-enable;
		};

		i2c0 {

			i2c0-xfer {
				rockchip,pins = <0x00 0x08 0x01 0xa0 0x00 0x09 0x01 0xa0>;
				phandle = <0x58>;
			};
		};

		i2c1 {

			i2c1-xfer {
				rockchip,pins = <0x00 0x12 0x01 0xa0 0x00 0x13 0x01 0xa0>;
				phandle = <0x5e>;
			};
		};

		i2c2 {

			i2c2-xfer {
				rockchip,pins = <0x02 0x0f 0x02 0xa0 0x02 0x10 0x02 0xa0>;
				phandle = <0x5f>;
			};
		};

		i2c3 {

			i2c3-xfer {
				rockchip,pins = <0x01 0x0c 0x04 0xa0 0x01 0x0d 0x04 0xa0>;
				phandle = <0x60>;
			};
		};

		tsadc {

			tsadc-otp-pin {
				rockchip,pins = <0x00 0x06 0x00 0xa1>;
				phandle = <0x72>;
			};

			tsadc-otp-out {
				rockchip,pins = <0x00 0x06 0x01 0xa1>;
				phandle = <0x73>;
			};
		};

		uart0 {

			uart0-xfer {
				rockchip,pins = <0x00 0x0a 0x01 0xa2 0x00 0x0b 0x01 0xa2>;
				phandle = <0x2b>;
			};

			uart0-cts {
				rockchip,pins = <0x00 0x0c 0x01 0xa1>;
				phandle = <0x2c>;
			};

			uart0-rts {
				rockchip,pins = <0x00 0x0d 0x01 0xa1>;
				phandle = <0x2d>;
			};
		};

		uart1 {

			uart1-xfer {
				rockchip,pins = <0x01 0x11 0x01 0xa2 0x01 0x10 0x01 0xa2>;
				phandle = <0x47>;
			};

			uart1-cts {
				rockchip,pins = <0x01 0x12 0x01 0xa1>;
				phandle = <0x48>;
			};

			uart1-rts {
				rockchip,pins = <0x01 0x13 0x01 0xa1>;
				phandle = <0x49>;
			};
		};

		uart2-m0 {

			uart2m0-xfer {
				rockchip,pins = <0x01 0x1a 0x02 0xa2 0x01 0x1b 0x02 0xa2>;
			};
		};

		uart2-m1 {

			uart2m1-xfer {
				rockchip,pins = <0x02 0x0c 0x02 0xa2 0x02 0x0e 0x02 0xa2>;
				phandle = <0x4e>;
			};
		};

		uart3-m0 {

			uart3m0-xfer {
				rockchip,pins = <0x00 0x10 0x02 0xa2 0x00 0x11 0x02 0xa2>;
			};

			uart3m0-cts {
				rockchip,pins = <0x00 0x12 0x02 0xa1>;
			};

			uart3m0-rts {
				rockchip,pins = <0x00 0x13 0x02 0xa1>;
			};
		};

		uart3-m1 {

			uart3m1-xfer {
				rockchip,pins = <0x01 0x0e 0x02 0xa2 0x01 0x0f 0x02 0xa2>;
				phandle = <0x4f>;
			};

			uart3m1-cts {
				rockchip,pins = <0x01 0x0c 0x02 0xa1>;
				phandle = <0x50>;
			};

			uart3m1-rts {
				rockchip,pins = <0x01 0x0d 0x02 0xa1>;
				phandle = <0x51>;
			};
		};

		uart4 {

			uart4-xfer {
				rockchip,pins = <0x01 0x1c 0x02 0xa2 0x01 0x1d 0x02 0xa2>;
				phandle = <0x52>;
			};

			uart4-cts {
				rockchip,pins = <0x01 0x1e 0x02 0xa1>;
				phandle = <0x53>;
			};

			uart4-rts {
				rockchip,pins = <0x01 0x1f 0x02 0xa1>;
				phandle = <0x54>;
			};
		};

		uart5 {

			uart5-xfer {
				rockchip,pins = <0x03 0x02 0x04 0xa2 0x03 0x01 0x04 0xa2>;
				phandle = <0x55>;
			};

			uart5-cts {
				rockchip,pins = <0x03 0x03 0x04 0xa1>;
				phandle = <0x56>;
			};

			uart5-rts {
				rockchip,pins = <0x03 0x05 0x04 0xa1>;
				phandle = <0x57>;
			};
		};

		spi0 {

			spi0-clk {
				rockchip,pins = <0x01 0x0f 0x03 0xa3>;
				phandle = <0x61>;
			};

			spi0-csn {
				rockchip,pins = <0x01 0x0e 0x03 0xa3>;
				phandle = <0x62>;
			};

			spi0-miso {
				rockchip,pins = <0x01 0x0d 0x03 0xa3>;
				phandle = <0x63>;
			};

			spi0-mosi {
				rockchip,pins = <0x01 0x0c 0x03 0xa3>;
				phandle = <0x64>;
			};

			spi0-clk-hs {
				rockchip,pins = <0x01 0x0f 0x03 0xa4>;
			};

			spi0-miso-hs {
				rockchip,pins = <0x01 0x0d 0x03 0xa4>;
			};

			spi0-mosi-hs {
				rockchip,pins = <0x01 0x0c 0x03 0xa4>;
			};
		};

		spi1 {

			spi1-clk {
				rockchip,pins = <0x03 0x0f 0x04 0xa3>;
				phandle = <0x65>;
			};

			spi1-csn0 {
				rockchip,pins = <0x03 0x09 0x04 0xa3>;
				phandle = <0x66>;
			};

			spi1-csn1 {
				rockchip,pins = <0x03 0x0a 0x02 0xa3>;
				phandle = <0x67>;
			};

			spi1-miso {
				rockchip,pins = <0x03 0x0e 0x04 0xa3>;
				phandle = <0x68>;
			};

			spi1-mosi {
				rockchip,pins = <0x03 0x0c 0x04 0xa3>;
				phandle = <0x69>;
			};

			spi1-clk-hs {
				rockchip,pins = <0x03 0x0f 0x04 0xa4>;
			};

			spi1-miso-hs {
				rockchip,pins = <0x03 0x0e 0x04 0xa4>;
			};

			spi1-mosi-hs {
				rockchip,pins = <0x03 0x0c 0x04 0xa4>;
			};
		};

		pdm {

			pdm-clk0m0 {
				rockchip,pins = <0x03 0x16 0x02 0xa1>;
			};

			pdm-clk0m1 {
				rockchip,pins = <0x02 0x16 0x01 0xa1>;
			};

			pdm-clk1 {
				rockchip,pins = <0x03 0x17 0x02 0xa1>;
			};

			pdm-sdi0m0 {
				rockchip,pins = <0x03 0x1b 0x02 0xa1>;
			};

			pdm-sdi0m1 {
				rockchip,pins = <0x02 0x15 0x02 0xa1>;
			};

			pdm-sdi1 {
				rockchip,pins = <0x03 0x18 0x02 0xa1>;
			};

			pdm-sdi2 {
				rockchip,pins = <0x03 0x19 0x02 0xa1>;
			};

			pdm-sdi3 {
				rockchip,pins = <0x03 0x1a 0x02 0xa1>;
			};

			pdm-clk0m0-sleep {
				rockchip,pins = <0x03 0x16 0x00 0xa5>;
			};

			pdm-clk0m1-sleep {
				rockchip,pins = <0x02 0x16 0x00 0xa5>;
			};

			pdm-clk1-sleep {
				rockchip,pins = <0x03 0x17 0x00 0xa5>;
			};

			pdm-sdi0m0-sleep {
				rockchip,pins = <0x03 0x1b 0x00 0xa5>;
			};

			pdm-sdi0m1-sleep {
				rockchip,pins = <0x02 0x15 0x00 0xa5>;
			};

			pdm-sdi1-sleep {
				rockchip,pins = <0x03 0x18 0x00 0xa5>;
			};

			pdm-sdi2-sleep {
				rockchip,pins = <0x03 0x19 0x00 0xa5>;
			};

			pdm-sdi3-sleep {
				rockchip,pins = <0x03 0x1a 0x00 0xa5>;
			};
		};

		i2s0 {

			i2s0-8ch-mclk {
				rockchip,pins = <0x03 0x11 0x02 0xa1>;
			};

			i2s0-8ch-sclktx {
				rockchip,pins = <0x03 0x13 0x02 0xa1>;
				phandle = <0x2f>;
			};

			i2s0-8ch-sclkrx {
				rockchip,pins = <0x03 0x0c 0x02 0xa1>;
				phandle = <0x30>;
			};

			i2s0-8ch-lrcktx {
				rockchip,pins = <0x03 0x12 0x02 0xa1>;
				phandle = <0x31>;
			};

			i2s0-8ch-lrckrx {
				rockchip,pins = <0x03 0x0d 0x02 0xa1>;
				phandle = <0x32>;
			};

			i2s0-8ch-sdo0 {
				rockchip,pins = <0x03 0x14 0x02 0xa1>;
				phandle = <0x33>;
			};

			i2s0-8ch-sdo1 {
				rockchip,pins = <0x03 0x10 0x02 0xa1>;
				phandle = <0x35>;
			};

			i2s0-8ch-sdo2 {
				rockchip,pins = <0x03 0x0f 0x02 0xa1>;
				phandle = <0x37>;
			};

			i2s0-8ch-sdo3 {
				rockchip,pins = <0x03 0x0e 0x02 0xa1>;
				phandle = <0x39>;
			};

			i2s0-8ch-sdi0 {
				rockchip,pins = <0x03 0x15 0x02 0xa1>;
				phandle = <0x34>;
			};

			i2s0-8ch-sdi1 {
				rockchip,pins = <0x03 0x0b 0x02 0xa1>;
				phandle = <0x36>;
			};

			i2s0-8ch-sdi2 {
				rockchip,pins = <0x03 0x09 0x02 0xa1>;
				phandle = <0x38>;
			};

			i2s0-8ch-sdi3 {
				rockchip,pins = <0x03 0x08 0x02 0xa1>;
				phandle = <0x3a>;
			};
		};

		i2s1 {

			i2s1-2ch-mclk {
				rockchip,pins = <0x02 0x13 0x01 0xa1>;
				phandle = <0x5a>;
			};

			i2s1-2ch-sclk {
				rockchip,pins = <0x02 0x12 0x01 0xa1>;
				phandle = <0x3b>;
			};

			i2s1-2ch-lrck {
				rockchip,pins = <0x02 0x11 0x01 0xa1>;
				phandle = <0x3c>;
			};

			i2s1-2ch-sdi {
				rockchip,pins = <0x02 0x15 0x01 0xa1>;
				phandle = <0x3d>;
			};

			i2s1-2ch-sdo {
				rockchip,pins = <0x02 0x14 0x01 0xa1>;
				phandle = <0x3e>;
			};
		};

		i2s2 {

			i2s2-2ch-mclk {
				rockchip,pins = <0x03 0x01 0x02 0xa1>;
			};

			i2s2-2ch-sclk {
				rockchip,pins = <0x03 0x02 0x02 0xa1>;
				phandle = <0x3f>;
			};

			i2s2-2ch-lrck {
				rockchip,pins = <0x03 0x03 0x02 0xa1>;
				phandle = <0x40>;
			};

			i2s2-2ch-sdi {
				rockchip,pins = <0x03 0x05 0x02 0xa1>;
				phandle = <0x41>;
			};

			i2s2-2ch-sdo {
				rockchip,pins = <0x03 0x07 0x02 0xa1>;
				phandle = <0x42>;
			};
		};

		sdmmc {

			sdmmc-clk {
				rockchip,pins = <0x01 0x1e 0x01 0xa6>;
				phandle = <0x7b>;
			};

			sdmmc-cmd {
				rockchip,pins = <0x01 0x1f 0x01 0xa4>;
				phandle = <0x7c>;
			};

			sdmmc-det {
				rockchip,pins = <0x00 0x03 0x01 0xa4>;
				phandle = <0x7d>;
			};

			sdmmc-bus1 {
				rockchip,pins = <0x01 0x1a 0x01 0xa4>;
			};

			sdmmc-bus4 {
				rockchip,pins = <0x01 0x1a 0x01 0xa4 0x01 0x1b 0x01 0xa4 0x01 0x1c 0x01 0xa4 0x01 0x1d 0x01 0xa4>;
				phandle = <0x7e>;
			};
		};

		sdio {

			sdio-clk {
				rockchip,pins = <0x01 0x15 0x01 0xa1>;
				phandle = <0x82>;
			};

			sdio-cmd {
				rockchip,pins = <0x01 0x14 0x01 0xa2>;
				phandle = <0x81>;
			};

			sdio-bus4 {
				rockchip,pins = <0x01 0x16 0x01 0xa2 0x01 0x17 0x01 0xa2 0x01 0x18 0x01 0xa2 0x01 0x19 0x01 0xa2>;
				phandle = <0x80>;
			};
		};

		emmc {

			emmc-clk {
				rockchip,pins = <0x01 0x09 0x02 0xa6>;
				phandle = <0x84>;
			};

			emmc-cmd {
				rockchip,pins = <0x01 0x0a 0x02 0xa4>;
				phandle = <0x85>;
			};

			emmc-rstnout {
				rockchip,pins = <0x01 0x0b 0x02 0xa1>;
			};

			emmc-bus1 {
				rockchip,pins = <0x01 0x00 0x02 0xa4>;
			};

			emmc-bus4 {
				rockchip,pins = <0x01 0x00 0x02 0xa4 0x01 0x01 0x02 0xa4 0x01 0x02 0x02 0xa4 0x01 0x03 0x02 0xa4>;
			};

			emmc-bus8 {
				rockchip,pins = <0x01 0x00 0x02 0xa4 0x01 0x01 0x02 0xa4 0x01 0x02 0x02 0xa4 0x01 0x03 0x02 0xa4 0x01 0x04 0x02 0xa4 0x01 0x05 0x02 0xa4 0x01 0x06 0x02 0xa4 0x01 0x07 0x02 0xa4>;
				phandle = <0x86>;
			};
		};

		flash {

			flash-cs0 {
				rockchip,pins = <0x01 0x08 0x01 0xa1>;
				phandle = <0x8d>;
			};

			flash-rdy {
				rockchip,pins = <0x01 0x09 0x01 0xa1>;
				phandle = <0x8f>;
			};

			flash-dqs {
				rockchip,pins = <0x01 0x0a 0x01 0xa1>;
				phandle = <0x91>;
			};

			flash-ale {
				rockchip,pins = <0x01 0x0b 0x01 0xa1>;
				phandle = <0x8a>;
			};

			flash-cle {
				rockchip,pins = <0x01 0x0c 0x01 0xa1>;
				phandle = <0x8c>;
			};

			flash-wrn {
				rockchip,pins = <0x01 0x0d 0x01 0xa1>;
				phandle = <0x90>;
			};

			flash-csl {
				rockchip,pins = <0x01 0x0e 0x01 0xa1>;
			};

			flash-rdn {
				rockchip,pins = <0x01 0x0f 0x01 0xa1>;
				phandle = <0x8e>;
			};

			flash-bus8 {
				rockchip,pins = <0x01 0x00 0x01 0xa7 0x01 0x01 0x01 0xa7 0x01 0x02 0x01 0xa7 0x01 0x03 0x01 0xa7 0x01 0x04 0x01 0xa7 0x01 0x05 0x01 0xa7 0x01 0x06 0x01 0xa7 0x01 0x07 0x01 0xa7>;
				phandle = <0x8b>;
			};
		};

		sfc {

			sfc-bus4 {
				rockchip,pins = <0x01 0x00 0x03 0xa1 0x01 0x01 0x03 0xa1 0x01 0x02 0x03 0xa1 0x01 0x03 0x03 0xa1>;
			};

			sfc-bus2 {
				rockchip,pins = <0x01 0x00 0x03 0xa1 0x01 0x01 0x03 0xa1>;
				phandle = <0x89>;
			};

			sfc-cs0 {
				rockchip,pins = <0x01 0x04 0x03 0xa1>;
				phandle = <0x88>;
			};

			sfc-clk {
				rockchip,pins = <0x01 0x09 0x03 0xa1>;
				phandle = <0x87>;
			};
		};

		lcdc {

			lcdc-rgb-dclk-pin {
				rockchip,pins = <0x03 0x00 0x01 0xa8>;
			};

			lcdc-rgb-m0-hsync-pin {
				rockchip,pins = <0x03 0x01 0x01 0xa8>;
			};

			lcdc-rgb-m0-vsync-pin {
				rockchip,pins = <0x03 0x02 0x01 0xa8>;
			};

			lcdc-rgb-m0-den-pin {
				rockchip,pins = <0x03 0x03 0x01 0xa8>;
			};

			lcdc-rgb888-m0-data-pins {
				rockchip,pins = <0x03 0x07 0x01 0xa6 0x03 0x06 0x01 0xa6 0x03 0x05 0x01 0xa6 0x03 0x04 0x01 0xa6 0x03 0x0b 0x01 0xa6 0x03 0x0a 0x01 0xa6 0x03 0x09 0x01 0xa6 0x03 0x08 0x01 0xa6 0x03 0x0f 0x01 0xa6 0x03 0x0e 0x01 0xa6 0x03 0x0d 0x01 0xa6 0x03 0x0c 0x01 0xa6 0x03 0x13 0x01 0xa6 0x03 0x12 0x01 0xa6 0x03 0x11 0x01 0xa6 0x03 0x10 0x01 0xa6 0x03 0x17 0x01 0xa6 0x03 0x16 0x01 0xa6 0x03 0x15 0x01 0xa6 0x03 0x14 0x01 0xa6 0x03 0x1b 0x01 0xa6 0x03 0x1a 0x01 0xa6 0x03 0x19 0x01 0xa6 0x03 0x18 0x01 0xa6>;
			};

			lcdc-rgb666-m0-data-pins {
				rockchip,pins = <0x03 0x07 0x01 0xa6 0x03 0x06 0x01 0xa6 0x03 0x05 0x01 0xa6 0x03 0x04 0x01 0xa6 0x03 0x0b 0x01 0xa6 0x03 0x0a 0x01 0xa6 0x03 0x09 0x01 0xa6 0x03 0x08 0x01 0xa6 0x03 0x0f 0x01 0xa6 0x03 0x0e 0x01 0xa6 0x03 0x0d 0x01 0xa6 0x03 0x0c 0x01 0xa6 0x03 0x13 0x01 0xa6 0x03 0x12 0x01 0xa6 0x03 0x11 0x01 0xa6 0x03 0x10 0x01 0xa6 0x03 0x15 0x01 0xa6 0x03 0x14 0x01 0xa6>;
			};

			lcdc-rgb565-m0-data-pins {
				rockchip,pins = <0x03 0x07 0x01 0xa6 0x03 0x06 0x01 0xa6 0x03 0x05 0x01 0xa6 0x03 0x04 0x01 0xa6 0x03 0x0b 0x01 0xa6 0x03 0x0a 0x01 0xa6 0x03 0x09 0x01 0xa6 0x03 0x08 0x01 0xa6 0x03 0x0f 0x01 0xa6 0x03 0x0e 0x01 0xa6 0x03 0x0d 0x01 0xa6 0x03 0x0c 0x01 0xa6 0x03 0x13 0x01 0xa6 0x03 0x12 0x01 0xa6 0x03 0x11 0x01 0xa6 0x03 0x10 0x01 0xa6>;
			};

			lcdc-rgb888-m1-data-pins {
				rockchip,pins = <0x03 0x06 0x01 0xa6 0x03 0x04 0x01 0xa6 0x03 0x0b 0x01 0xa6 0x03 0x0a 0x01 0xa6 0x03 0x0d 0x01 0xa6 0x03 0x13 0x01 0xa6 0x03 0x12 0x01 0xa6 0x03 0x11 0x01 0xa6 0x03 0x10 0x01 0xa6 0x03 0x17 0x01 0xa6 0x03 0x16 0x01 0xa6 0x03 0x15 0x01 0xa6 0x03 0x14 0x01 0xa6 0x03 0x1b 0x01 0xa6 0x03 0x1a 0x01 0xa6 0x03 0x19 0x01 0xa6 0x03 0x18 0x01 0xa6>;
			};

			lcdc-rgb666-m1-data-pins {
				rockchip,pins = <0x03 0x06 0x01 0xa6 0x03 0x04 0x01 0xa6 0x03 0x0b 0x01 0xa6 0x03 0x0a 0x01 0xa6 0x03 0x0d 0x01 0xa6 0x03 0x13 0x01 0xa6 0x03 0x12 0x01 0xa6 0x03 0x11 0x01 0xa6 0x03 0x10 0x01 0xa6 0x03 0x15 0x01 0xa6 0x03 0x14 0x01 0xa6>;
			};

			lcdc-rgb565-m1-data-pins {
				rockchip,pins = <0x03 0x06 0x01 0xa6 0x03 0x04 0x01 0xa6 0x03 0x0b 0x01 0xa6 0x03 0x0a 0x01 0xa6 0x03 0x0d 0x01 0xa6 0x03 0x13 0x01 0xa6 0x03 0x12 0x01 0xa6 0x03 0x11 0x01 0xa6 0x03 0x10 0x01 0xa6>;
			};
		};

		pwm0 {

			pwm0-pin {
				rockchip,pins = <0x00 0x0f 0x01 0xa1>;
				phandle = <0x6a>;
			};
		};

		pwm1 {

			pwm1-pin {
				rockchip,pins = <0x00 0x10 0x01 0xa1>;
				phandle = <0x6b>;
			};
		};

		pwm2 {

			pwm2-pin {
				rockchip,pins = <0x02 0x0d 0x01 0xa1>;
				phandle = <0x6c>;
			};
		};

		pwm3 {

			pwm3-pin {
				rockchip,pins = <0x00 0x11 0x01 0xa1>;
				phandle = <0x6d>;
			};
		};

		pwm4 {

			pwm4-pin {
				rockchip,pins = <0x03 0x12 0x03 0xa1>;
				phandle = <0x6e>;
			};
		};

		pwm5 {

			pwm5-pin {
				rockchip,pins = <0x03 0x13 0x03 0xa1>;
				phandle = <0x6f>;
			};
		};

		pwm6 {

			pwm6-pin {
				rockchip,pins = <0x03 0x14 0x03 0xa1>;
				phandle = <0x70>;
			};
		};

		pwm7 {

			pwm7-pin {
				rockchip,pins = <0x03 0x15 0x03 0xa1>;
				phandle = <0x71>;
			};
		};

		gmac {

			rmii-pins {
				rockchip,pins = <0x02 0x00 0x02 0xa8 0x02 0x01 0x02 0xa8 0x02 0x02 0x02 0xa8 0x02 0x03 0x02 0xa1 0x02 0x04 0x02 0xa1 0x02 0x05 0x02 0xa1 0x02 0x06 0x02 0xa1 0x02 0x07 0x02 0xa1 0x02 0x09 0x02 0xa1>;
				phandle = <0x79>;
			};

			mac-refclk-12ma {
				rockchip,pins = <0x02 0x0a 0x02 0xa8>;
				phandle = <0x7a>;
			};

			mac-refclk {
				rockchip,pins = <0x02 0x0a 0x02 0xa1>;
			};
		};

		cif-m0 {

			cif-clkout-m0 {
				rockchip,pins = <0x02 0x0b 0x01 0xa1>;
			};

			dvp-d2d9-m0 {
				rockchip,pins = <0x02 0x00 0x01 0xa1 0x02 0x01 0x01 0xa1 0x02 0x02 0x01 0xa1 0x02 0x03 0x01 0xa1 0x02 0x04 0x01 0xa1 0x02 0x05 0x01 0xa1 0x02 0x06 0x01 0xa1 0x02 0x07 0x01 0xa1 0x02 0x08 0x01 0xa1 0x02 0x09 0x01 0xa1 0x02 0x0a 0x01 0xa1 0x02 0x0b 0x01 0xa1>;
			};

			dvp-d0d1-m0 {
				rockchip,pins = <0x02 0x0c 0x01 0xa1 0x02 0x0e 0x01 0xa1>;
			};

			d10-d11-m0 {
				rockchip,pins = <0x02 0x0f 0x01 0xa1 0x02 0x10 0x01 0xa1>;
			};
		};

		cif-m1 {

			cif-clkout-m1 {
				rockchip,pins = <0x03 0x18 0x03 0xa1>;
			};

			dvp-d2d9-m1 {
				rockchip,pins = <0x03 0x03 0x03 0xa1 0x03 0x05 0x03 0xa1 0x03 0x07 0x03 0xa1 0x03 0x08 0x03 0xa1 0x03 0x09 0x03 0xa1 0x03 0x0c 0x03 0xa1 0x03 0x0e 0x03 0xa1 0x03 0x0f 0x03 0xa1 0x03 0x19 0x03 0xa1 0x03 0x1a 0x03 0xa1 0x03 0x1b 0x03 0xa1 0x03 0x18 0x03 0xa1>;
			};

			dvp-d0d1-m1 {
				rockchip,pins = <0x03 0x01 0x03 0xa1 0x03 0x02 0x03 0xa1>;
			};

			d10-d11-m1 {
				rockchip,pins = <0x03 0x16 0x03 0xa1 0x03 0x17 0x03 0xa1>;
			};
		};

		isp {

			isp-prelight {
				rockchip,pins = <0x03 0x19 0x04 0xa1>;
			};
		};

		bluetooth-pins {

			bt-reset {
				rockchip,pins = <0x00 0x00 0x00 0xa9>;
				phandle = <0x4b>;
			};

			bt-wake-dev {
				rockchip,pins = <0x00 0x01 0x00 0xa1>;
				phandle = <0x4c>;
			};

			bt-wake-host {
				rockchip,pins = <0x00 0x07 0x00 0xa1>;
				phandle = <0x4d>;
			};
		};

		headphone {

			hp-det {
				rockchip,pins = <0x02 0x16 0x00 0xa2>;
				phandle = <0xb6>;
			};
		};

		gpio-btns {

			btn-pins-ctrl {
				rockchip,pins = <0x01 0x0c 0x00 0xa2 0x01 0x0d 0x00 0xa2 0x01 0x0e 0x00 0xa2 0x01 0x0f 0x00 0xa2 0x02 0x00 0x00 0xa2 0x02 0x02 0x00 0xa2 0x02 0x03 0x00 0xa2 0x02 0x04 0x00 0xa2 0x02 0x05 0x00 0xa2 0x02 0x06 0x00 0xa2 0x02 0x07 0x00 0xa2 0x02 0x08 0x00 0xa2 0x02 0x09 0x00 0xa2 0x02 0x0a 0x00 0xa2 0x02 0x0b 0x00 0xa2>;
				phandle = <0xaf>;
			};
		};

		gpio-leds {

			led-pins {
				rockchip,pins = <0x03 0x0a 0x00 0xa1 0x03 0x0b 0x00 0xa1 0x03 0x14 0x00 0xa1 0x03 0x15 0x00 0xa1 0x03 0x16 0x00 0xa1>;
				phandle = <0xae>;
			};
		};

		pmic {

			pmic-int {
				rockchip,pins = <0x00 0x11 0x00 0xa2>;
				phandle = <0x59>;
			};

			soc_slppin_gpio {
				rockchip,pins = <0x00 0x04 0x00 0xaa>;
			};

			soc_slppin_rst {
				rockchip,pins = <0x00 0x04 0x02 0xa1>;
			};

			soc_slppin_slp {
				rockchip,pins = <0x00 0x04 0x01 0xa1>;
			};
		};

		sdio-pwrseq {

			wifi-enable-h {
				rockchip,pins = <0x00 0x02 0x00 0xa1>;
				phandle = <0xbc>;
			};
		};

		speaker {

			spk-amp-enable-h {
				rockchip,pins = <0x02 0x0d 0x00 0xa1>;
				phandle = <0xb5>;
			};
		};
	};

	chosen {
		stdout-path = "serial2:115200n8";
	};

	adc-joystick {
		compatible = "adc-joystick";
		io-channels = <0xab 0x00 0xab 0x01>;
		poll-interval = <0x64>;
		#address-cells = <0x01>;
		#size-cells = <0x00>;

		axis@0 {
			reg = <0x00>;
			abs-flat = <0x0a>;
			abs-fuzz = <0x0a>;
			abs-range = <0x352 0xaf>;
			linux,code = <0x01>;
		};

		axis@1 {
			reg = <0x01>;
			abs-flat = <0x0a>;
			abs-fuzz = <0x0a>;
			abs-range = <0x320 0xbe>;
			linux,code = <0x00>;
		};
	};

	adc-keys {
		compatible = "adc-keys";
		io-channels = <0xab 0x02>;
		io-channel-names = "buttons";
		keyup-threshold-microvolt = <0x1b7740>;
		poll-interval = <0x3c>;

		button-1 {
			label = "HAPPY1";
			linux,code = <0x2c0>;
			press-threshold-microvolt = <0x3a98>;
		};

		button-2 {
			label = "HAPPY2";
			linux,code = <0x2c1>;
			press-threshold-microvolt = <0x493e0>;
		};
	};

	backlight {
		compatible = "pwm-backlight";
		power-supply = <0xac>;
		pwms = <0xad 0x00 0x61a8 0x00>;
		phandle = <0x97>;
	};

	battery {
		compatible = "simple-battery";
		charge-full-design-microamp-hours = <0x2dc6c0>;
		charge-term-current-microamp = <0x493e0>;
		constant-charge-current-max-microamp = <0x16e360>;
		constant-charge-voltage-max-microvolt = <0x401640>;
		factory-internal-resistance-micro-ohms = <0x2bf20>;
		ocv-capacity-celsius = <0x14>;
		ocv-capacity-table-0 = <0x3ea710 0x64 0x3e1e58 0x5f 0x3d4f50 0x5a 0x3ca758 0x55 0x3c3610 0x50 0x3ba1a0 0x4b 0x3b2888 0x46 0x3acac8 0x41 0x3a8090 0x3c 0x3a3a40 0x37 0x3a0390 0x32 0x39cce0 0x2d 0x399630 0x28 0x395f80 0x23 0x3930a0 0x1e 0x38fdd8 0x19 0x38bb70 0x14 0x386968 0x0f 0x383a88 0x0a 0x375028 0x05 0x33e140 0x00>;
		voltage-max-design-microvolt = <0x40d990>;
		voltage-min-design-microvolt = <0x33e140>;
		phandle = <0x5d>;
	};

	gpio-leds {
		compatible = "gpio-leds";
		pinctrl-names = "default";
		pinctrl-0 = <0xae>;

		led-0 {
			color = <0x01>;
			gpios = <0x99 0x14 0x00>;
			phandle = <0xb2>;
		};

		led-1 {
			color = <0x02>;
			gpios = <0x99 0x15 0x00>;
			phandle = <0xb3>;
		};

		led-2 {
			color = <0x03>;
			gpios = <0x99 0x16 0x00>;
			phandle = <0xb4>;
		};

		led-3 {
			color = <0x00>;
			function = "status";
			gpios = <0x99 0x0b 0x00>;
		};

		led-4 {
			color = <0x01>;
			function = "charging";
			gpios = <0x99 0x0a 0x00>;
		};
	};

	gpio-keys {
		compatible = "gpio-keys";
		pinctrl-0 = <0xaf>;
		pinctrl-names = "default";

		button-a {
			gpios = <0xb0 0x08 0x01>;
			label = "EAST";
			linux,code = <0x131>;
		};

		button-b {
			gpios = <0xb0 0x09 0x01>;
			label = "SOUTH";
			linux,code = <0x130>;
		};

		button-down {
			gpios = <0xb1 0x0d 0x01>;
			label = "DPAD-DOWN";
			linux,code = <0x221>;
		};

		button-home {
			gpios = <0xb0 0x00 0x01>;
			label = "HOME";
			linux,code = <0x13c>;
		};

		button-l1 {
			gpios = <0xb0 0x06 0x01>;
			label = "TL";
			linux,code = <0x136>;
		};

		button-l2 {
			gpios = <0xb0 0x04 0x01>;
			label = "TL2";
			linux,code = <0x138>;
		};

		button-left {
			gpios = <0xb1 0x0e 0x01>;
			label = "DPAD-LEFT";
			linux,code = <0x222>;
		};

		button-r1 {
			gpios = <0xb0 0x07 0x01>;
			label = "TR";
			linux,code = <0x137>;
		};

		button-r2 {
			gpios = <0xb0 0x05 0x01>;
			label = "TR2";
			linux,code = <0x139>;
		};

		button-right {
			gpios = <0xb1 0x0f 0x01>;
			label = "DPAD-RIGHT";
			linux,code = <0x223>;
		};

		button-select {
			gpios = <0xb0 0x03 0x01>;
			label = "SELECT";
			linux,code = <0x13a>;
		};

		button-start {
			gpios = <0xb0 0x02 0x01>;
			label = "START";
			linux,code = <0x13b>;
		};

		button-up {
			gpios = <0xb1 0x0c 0x01>;
			label = "DPAD-UP";
			linux,code = <0x220>;
		};

		button-x {
			gpios = <0xb0 0x0b 0x01>;
			label = "NORTH";
			linux,code = <0x133>;
		};

		button-y {
			gpios = <0xb0 0x0a 0x01>;
			label = "WEST";
			linux,code = <0x134>;
		};
	};

	multi-led {
		compatible = "leds-group-multicolor";
		color = <0x09>;
		function = "kbd_backlight";
		leds = <0xb2 0xb3 0xb4>;
	};

	audio-amplifier {
		compatible = "simple-audio-amplifier";
		enable-gpios = <0xb0 0x0d 0x00>;
		pinctrl-0 = <0xb5>;
		pinctrl-names = "default";
		sound-name-prefix = "Speaker Amp";
		phandle = <0xb7>;
	};

	sound {
		compatible = "simple-audio-card";
		pinctrl-0 = <0xb6>;
		pinctrl-names = "default";
		simple-audio-card,name = "rk817_ext";
		simple-audio-card,aux-devs = <0xb7>;
		simple-audio-card,format = "i2s";
		simple-audio-card,hp-det-gpio = <0xb0 0x16 0x00>;
		simple-audio-card,mclk-fs = <0x100>;
		simple-audio-card,widgets = "Microphone\0Mic Jack\0Headphone\0Headphones\0Speaker\0Internal Speakers";
		simple-audio-card,routing = "MICL\0Mic Jack\0Headphones\0HPOL\0Headphones\0HPOR\0Internal Speakers\0Speaker Amp OUTL\0Internal Speakers\0Speaker Amp OUTR\0Speaker Amp INL\0HPOL\0Speaker Amp INR\0HPOR";
		simple-audio-card,pin-switches = "Internal Speakers";

		simple-audio-card,codec {
			sound-dai = <0xb8>;
		};

		simple-audio-card,cpu {
			sound-dai = <0xb9>;
		};
	};

	pwm-vibrator-l {
		compatible = "pwm-vibrator";
		pwm-names = "enable";
		pwms = <0xba 0x00 0x61a8 0x00>;
	};

	pwm-vibrator-r {
		compatible = "pwm-vibrator";
		pwm-names = "enable";
		pwms = <0xbb 0x00 0x61a8 0x00>;
	};

	sdio-pwrseq {
		compatible = "mmc-pwrseq-simple";
		clocks = <0xb8 0x01>;
		clock-names = "ext_clock";
		pinctrl-0 = <0xbc>;
		pinctrl-names = "default";
		post-power-on-delay-ms = <0xc8>;
		reset-gpios = <0x4a 0x02 0x01>;
		phandle = <0x83>;
	};

	vccsys-regulator {
		compatible = "regulator-fixed";
		regulator-name = "vcc3v8_sys";
		regulator-always-on;
		regulator-min-microvolt = <0x39fbc0>;
		regulator-max-microvolt = <0x39fbc0>;
		phandle = <0x5b>;
	};
};
